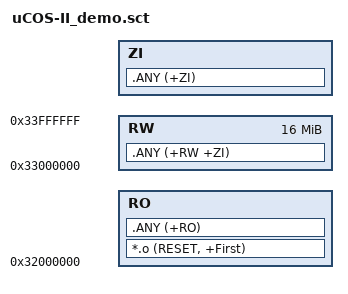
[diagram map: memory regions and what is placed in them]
; *************************************************************
; *** Scatter-Loading Description File generated by uVision ***
; *************************************************************
/*
LR_ROM1 0x00000000 0x00080000  {    ; load region size_region
  RO 0x00000000 0x00080000  {  ; load address = execution address
   *.o (Init_2440, +First)
   ;*(InRoot$$Sections)
   .ANY (+RO)
  }
  RW 0x30000000 0x4000000  {  ; RW data
   .ANY (+RW +ZI)
  }
  ZI  +0 {
   .ANY (+ZI)
  }
}
*/
/*
LR_ROM1 0x30000000 0x01000000  {    ; load region size_region
  RO 0x30000000 0x01000000  {  ; load address = execution address
   2440_init.o (Init_2440, +First)
   .ANY (+RO)
  }
  RW 0x31000000 0x01000000  {  ; RW data
   .ANY (+RW)
  }
  ZI  +0 {
   .ANY (+ZI)
  }
}
*/
LR_IROM1 0x32000000 0x01000000  {    ; load region size_region
  RO +0  {  ; load address = execution address
   *.o (RESET, +First)
   ;(InRoot$$Sections)
   .ANY (+RO)
  }
  RW 0x33000000 0x01000000 {  ; RW data
   .ANY (+RW +ZI)
  }
  ZI +0  {  ; ZI data
   .ANY (+ZI)
  }
}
